# max32620 register map
Vendor: Maxim Integrated; Series: ARMCM4; File version: 1.1
CPU: CM4 r1p0, little endian, no MPU, FPU, 3 interrupt priority bits
Registers are 32-bit, read-write, reset 0x0 unless marked. A register's access mark holds for its fields unless they carry their own. Offsets are from the block's base; [hi:lo] are bit positions.

## MAA — MAA Cryptographic Engine
Base 0x40007800
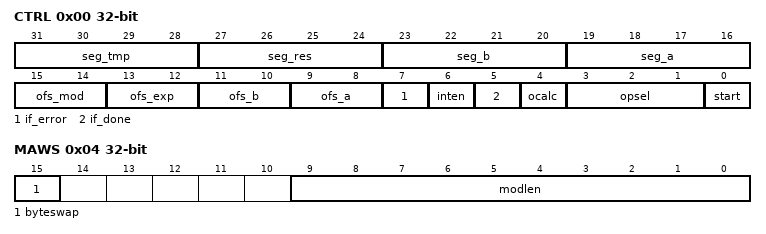
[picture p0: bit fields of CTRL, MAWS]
0x00 CTRL — MAA Control, Configuration and Status
  [31:28] seg_tmp — Temporary Memory Segment Select
  [27:24] seg_res — Result Memory Segment Select
  [23:20] seg_b — Operand B Memory Segment Select
  [19:16] seg_a — Operand A Memory Segment Select
  [15:14] ofs_mod — Modulus Memory Select
  [13:12] ofs_exp — Exponent Memory Offset Select
  [11:10] ofs_b — Operand B Memory Offset Select
  [9:8] ofs_a — Operand A Memory Offset Select
  [7] if_error — Interrupt Flag - Error
  [6] inten — MAA Interrupt Enable
  [5] if_done — Interrupt Flag - Calculation Done
  [4] ocalc — Optimized Calculation Control
  [3:1] opsel — Select Operation Type
    0=EXP (Exponentiation.); 1=SQR (Square operation.); 2=MUL (Multiply.); 3=SQRMUL (Square operation followed by multiply.); 4=ADD (Addition.); 5=SUB (Subtraction.)
  [0] start — Start MAA Calculation
0x04 MAWS — MAA Word (Operand) Size, Big/Little Endian Mode Select
  [15] byteswap — Big Endian Byte Mode
  [9:0] modlen — MAA Word Size

## WDT0 — Watchdog Timers
Base 0x40008000
Same registers: WDT1 0x40009000
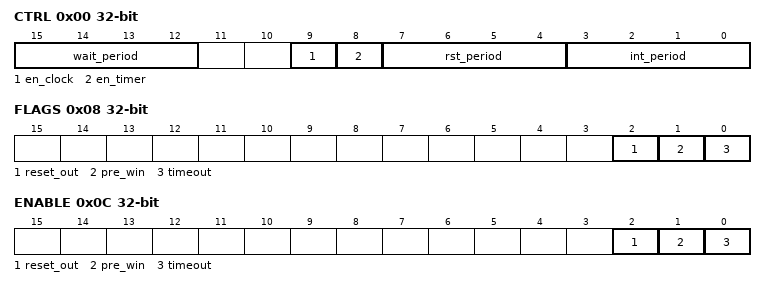
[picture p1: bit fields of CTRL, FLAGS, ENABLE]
0x00 CTRL — WDT0 - Watchdog Timer Control Register
  [15:12] wait_period — Period from WDT Clear to Clear Window Begin
    0=2_31_CLKS (2^31 WDT clocks.); 1=2_30_CLKS (2^30 WDT clocks.); 2=2_29_CLKS (2^29 WDT clocks.); 3=2_28_CLKS (2^28 WDT clocks.); 4=2_27_CLKS (2^27 WDT clocks); 5=2_26_CLKS (2^26 WDT clocks); 6=2_25_CLKS (2^25 WDT clocks); 7=2_24_CLKS (2^24 WDT clocks); 8=2_23_CLKS (2^23 WDT clocks); 9=2_22_CLKS (2^22 WDT clocks.); 10=2_21_CLKS (2^21 WDT clocks.); 11=2_20_CLKS (2^20 WDT clocks.); 12=2_19_CLKS (2^19 WDT clocks.); 13=2_18_CLKS (2^18 WDT clocks.); 14=2_17_CLKS (2^17 WDT clocks.); 15=2_16_CLKS (2^16 WDT clocks.)
  [9] en_clock — Watchdog Clock Gate
    0=DISABLE (WDT Clock Gate Control Disable); 1=ENABLE (WDT Clock Gate Control Enable)
  [8] en_timer — Watchdg Timer Enable
  [7:4] rst_period — Period from WDT Clear to Reset Flag Set
    0=2_31_CLKS (2^31 WDT clocks.); 1=2_30_CLKS (2^30 WDT clocks.); 2=2_29_CLKS (2^29 WDT clocks.); 3=2_28_CLKS (2^28 WDT clocks.); 4=2_27_CLKS (2^27 WDT clocks.); 5=2_26_CLKS (2^26 WDT clocks.); 6=2_25_CLKS (2^25 WDT clocks.); 7=2_24_CLKS (2^24 WDT clocks.); 8=2_23_CLKS (2^23 WDT clocks.); 9=2_22_CLKS (2^22 WDT clocks.); 10=2_21_CLKS (2^21 WDT clocks.); 11=2_20_CLKS (2^20 WDT clocks.); 12=2_19_CLKS (2^19 WDT clocks.); 13=2_18_CLKS (2^18 WDT clocks.); 14=2_17_CLKS (2^17 WDT clocks.); 15=2_16_CLKS (2^16 WDT clocks.)
  [3:0] int_period — Period from WDT Clear to Interrupt Flag Set
    0=2_31_CLKS (2^31 WDT clocks); 1=2_30_CLKS (2^30 WDT clocks); 2=2_29_CLKS (2^29 WDT clocks); 3=2_28_CLKS (2^28 WDT clocks); 4=2_27_CLKS (2^27 WDT clocks); 5=2_26_CLKS (2^26 WDT clocks); 6=2_25_CLKS (2^25 WDT clocks); 7=2_24_CLKS (2^24 WDT clocks); 8=2_23_CLKS (2^23 WDT clocks); 9=2_22_CLKS (2^22 WDT clocks); 10=2_21_CLKS (2^21 WDT clocks); 11=2_20_CLKS (2^20 WDT clocks); 12=2_19_CLKS (2^19 WDT clocks); 13=2_18_CLKS (2^18 WDT clocks); 14=2_17_CLKS (2^17 WDT clocks); 15=2_16_CLKS (2^16 WDT clocks)
0x04 CLEAR — WDT0 - Watchdog Clear Register (Feed Dog)
0x08 FLAGS — WDT0 - Watchdog Interrupt and Reset Flags
  [2] reset_out write-1-clears — Watchdog Reset Flag
  [1] pre_win write-1-clears — Watchdog Pre-Window Clear Interrupt Flag
  [0] timeout write-1-clears — Watchdog Timeout Interrupt Flag
0x0C ENABLE — WDT0 - Interrupt/Reset Enable/Disable Controls
  [2] reset_out — Enable Watchdog Reset Output
  [1] pre_win — Enable Watchdog Pre-Window Reset Interrupt
  [0] timeout — Enable Watchdog Interrupt
0x14 LOCK_CTRL — WDT0 - Register Setting Lock for WDT0_CTRL
  [7:0] wdlock — Lock for WDT CTRL Register
